AUTOSAR XML (schema 4-0-3)
standard types defined: Boolean, UInt16, UInt32, UInt8
package /AUTOSAR_Platform/DataConstrs
  range DC_Boolean: raw 0..1
  range DC_UInt16: raw 0..65535
  range DC_UInt8: raw 0..255
package /PATAC/MSM/ComponentTypes
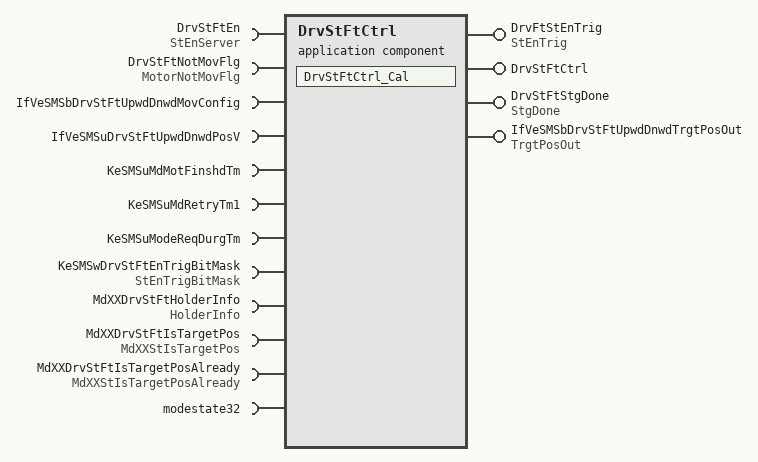
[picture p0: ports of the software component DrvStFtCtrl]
  application sw component type DrvStFtCtrl
    4 x provide port:
      DrvFtStEnTrig: nonqueued-sender-com-spec{data-element=StEnTrig/Val, init-value=0}, provided-interface=StEnTrig
      DrvStFtCtrl: server-com-spec{operation=Cal, queue-length=1}, provided-interface=DrvStFtCtrl
      DrvStFtStgDone: nonqueued-sender-com-spec{data-element=StgDone/Val, init-value=0}, provided-interface=StgDone
      IfVeSMSbDrvStFtUpwdDnwdTrgtPosOut: nonqueued-sender-com-spec{data-element=TrgtPosOut/Val, init-value=0}, provided-interface=TrgtPosOut
    12 x require port:
      DrvStFtEn: required-com-specs=[Clear, Get, Set], required-interface=StEnServer
      DrvStFtNotMovFlg: nonqueued-receiver-com-spec{data-element=MotorNotMovFlg/Val, filter=data-filter-type=ALWAYS, init-value=0}, required-interface=MotorNotMovFlg
      IfVeSMSbDrvStFtUpwdDnwdMovConfig: nonqueued-receiver-com-spec{data-element=IfVeSMSbDrvStFtUpwdDnwdMovConfig/Val, filter=data-filter-type=ALWAYS, init-value=0}, required-interface=IfVeSMSbDrvStFtUpwdDnwdMovConfig
      IfVeSMSuDrvStFtUpwdDnwdPosV: nonqueued-receiver-com-spec{data-element=IfVeSMSuDrvStFtUpwdDnwdPosV/Val, filter=data-filter-type=ALWAYS, init-value=0}, required-interface=IfVeSMSuDrvStFtUpwdDnwdPosV
      KeSMSuMdMotFinshdTm: parameter-require-com-spec{init-value=0, parameter=KeSMSuMdMotFinshdTm/Val}, required-interface=KeSMSuMdMotFinshdTm
      KeSMSuMdRetryTm1: parameter-require-com-spec{init-value=0, parameter=KeSMSuMdRetryTm1/Val}, required-interface=KeSMSuMdRetryTm1
      KeSMSuModeReqDurgTm: parameter-require-com-spec{init-value=0, parameter=KeSMSuModeReqDurgTm/Val}, required-interface=KeSMSuModeReqDurgTm
      KeSMSwDrvStFtEnTrigBitMask: parameter-require-com-spec{init-value=1545, parameter=StEnTrigBitMask/Val}, required-interface=StEnTrigBitMask
      MdXXDrvStFtHolderInfo: nonqueued-receiver-com-spec{data-element=HolderInfo/Val, filter=data-filter-type=ALWAYS, init-value=0}, required-interface=HolderInfo
      MdXXDrvStFtIsTargetPos: nonqueued-receiver-com-spec{data-element=MdXXStIsTargetPos/Val, filter=data-filter-type=ALWAYS, init-value=0}, required-interface=MdXXStIsTargetPos
      MdXXDrvStFtIsTargetPosAlready: nonqueued-receiver-com-spec{data-element=MdXXStIsTargetPosAlready/Val, filter=data-filter-type=ALWAYS, init-value=0}, required-interface=MdXXStIsTargetPosAlready
      modestate32: nonqueued-receiver-com-spec{data-element=modestate32/Val, filter=data-filter-type=ALWAYS, init-value=0}, required-interface=modestate32
    behavior DrvStFtCtrl_InternalBehavior
      operation invoked event OIT_DrvStFtCtrl_Cal_DrvStFtCtrl_Cal: start-on-event=DrvStFtCtrl_Cal, operation=DrvStFtCtrl.Cal
      runnable DrvStFtCtrl_Cal
        data-receive-point-by-arguments:
          7 x access:
            REC_DrvStFtNotMovFlg_Val: accessed-variable=DrvStFtNotMovFlg.Val
            REC_IfVeSMSbDrvStFtUpwdDnwdMovConfig_Val: accessed-variable=IfVeSMSbDrvStFtUpwdDnwdMovConfig.Val
            REC_IfVeSMSuDrvStFtUpwdDnwdPosV_Val: accessed-variable=IfVeSMSuDrvStFtUpwdDnwdPosV.Val
            REC_MdXXDrvStFtHolderInfo_Val: accessed-variable=MdXXDrvStFtHolderInfo.Val
            REC_MdXXDrvStFtIsTargetPos_Val: accessed-variable=MdXXDrvStFtIsTargetPos.Val
            REC_MdXXDrvStFtIsTargetPosAlready_Val: accessed-variable=MdXXDrvStFtIsTargetPosAlready.Val
            REC_modestate32_Val: accessed-variable=modestate32.Val
        data-send-points:
          access SEND_DrvFtStEnTrig_Val: accessed-variable=DrvFtStEnTrig.Val
          access SEND_DrvStFtStgDone_Val: accessed-variable=DrvStFtStgDone.Val
          access SEND_IfVeSMSbDrvStFtUpwdDnwdTrgtPosOut_Val: accessed-variable=IfVeSMSbDrvStFtUpwdDnwdTrgtPosOut.Val
        4 x parameter access:
          PA_KeSMSuMdMotFinshdTm_Val: accessed-parameter=KeSMSuMdMotFinshdTm.Val
          PA_KeSMSuMdRetryTm1_Val: accessed-parameter=KeSMSuMdRetryTm1.Val
          PA_KeSMSuModeReqDurgTm_Val: accessed-parameter=KeSMSuModeReqDurgTm.Val
          PA_KeSMSwDrvStFtEnTrigBitMask_Val: accessed-parameter=KeSMSwDrvStFtEnTrigBitMask.Val
        sync call SC_DrvStFtEn_Get: operation=DrvStFtEn.Get, timeout=0
  swc implementation DrvStFtCtrl_Implementation: behavior=DrvStFtCtrl_InternalBehavior
    code-descriptors:
      code Default: artifact-descriptors=autosar-engineering-object={short-label=Default, category=SWSRC}
package /PATAC/MSM/ModeAdjust/CalPortInterface
  parameter interface KeSMSuMdMotFinshdTm
    parameter data prototype Val: sw-calibration-access=READ-WRITE, type=UInt16
  parameter interface KeSMSuModeReqDurgTm
    parameter data prototype Val: sw-calibration-access=READ-WRITE, type=UInt16
  parameter interface StEnTrigBitMask
    parameter data prototype Val: sw-calibration-access=READ-WRITE, type=UInt32
package /PATAC/MSM/ModeAdjust/Interfaces
  sender receiver interface IfVeSMSuDrvStFtUpwdDnwdPosV: invalidation-policy{data-element=IfVeSMSuDrvStFtUpwdDnwdPosV/Val, handle-invalid=DONT-INVALIDATE}
    data Val: type=Boolean
package /PATAC/MSM/ModeAdjust/PortInterface
  client server interface DrvStFtCtrl
    operation Cal
  client server interface StEnServer
    operation Clear
      arg data: type=UInt8, direction=IN, server-argument-impl-policy=USE-ARGUMENT-TYPE
    operation Get
      arg data: type=UInt32, direction=OUT, server-argument-impl-policy=USE-ARGUMENT-TYPE
    operation Set
      arg data: type=UInt8, direction=IN, server-argument-impl-policy=USE-ARGUMENT-TYPE
  8 x sender receiver interface:
    HolderInfo: invalidation-policy{data-element=HolderInfo/Val, handle-invalid=DONT-INVALIDATE}
      data Val: type=UInt32
    MdXXStIsTargetPos: invalidation-policy{data-element=MdXXStIsTargetPos/Val, handle-invalid=DONT-INVALIDATE}
      data Val: type=UInt32
    MdXXStIsTargetPosAlready: invalidation-policy{data-element=MdXXStIsTargetPosAlready/Val, handle-invalid=DONT-INVALIDATE}
      data Val: type=UInt32
    modestate32: invalidation-policy{data-element=modestate32/Val, handle-invalid=DONT-INVALIDATE}
      data Val: type=UInt32
    MotorNotMovFlg: invalidation-policy{data-element=MotorNotMovFlg/Val, handle-invalid=DONT-INVALIDATE}
      data Val: type=Boolean
    StEnTrig: invalidation-policy{data-element=StEnTrig/Val, handle-invalid=DONT-INVALIDATE}
      data Val: type=Boolean
    StgDone: invalidation-policy{data-element=StgDone/Val, handle-invalid=DONT-INVALIDATE}
      data Val: type=Boolean
    TrgtPosOut: invalidation-policy{data-element=TrgtPosOut/Val, handle-invalid=DONT-INVALIDATE}
      data Val: type=Boolean
package /PATAC/MSM/PortInterfaces
  parameter interface KeSMSuMdRetryTm1
    parameter data prototype Val: sw-calibration-access=READ-WRITE, type=UInt8
  sender receiver interface IfVeSMSbDrvStFtUpwdDnwdMovConfig: invalidation-policy{data-element=IfVeSMSbDrvStFtUpwdDnwdMovConfig/Val, handle-invalid=DONT-INVALIDATE}
    data Val: type=Boolean
